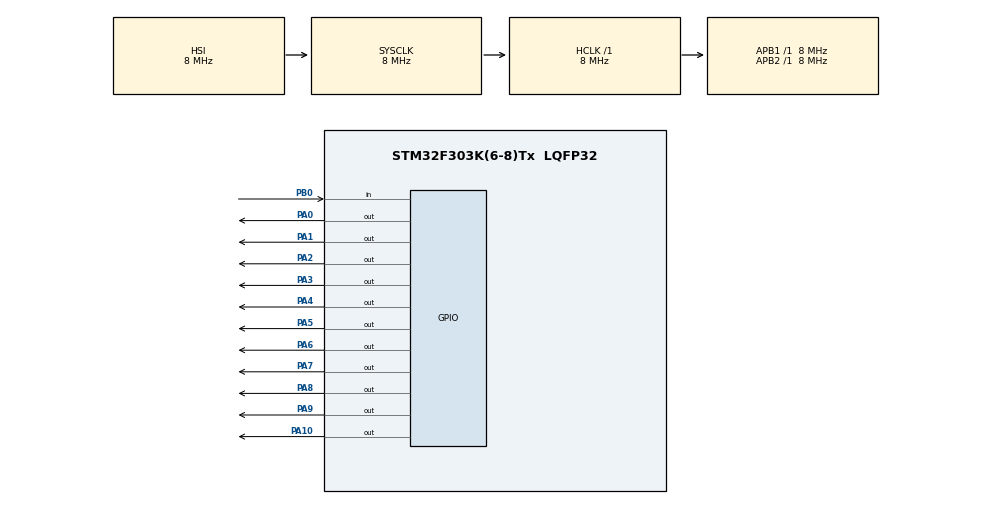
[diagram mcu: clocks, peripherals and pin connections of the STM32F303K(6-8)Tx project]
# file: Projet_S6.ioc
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Mcu.Family=STM32F3
Mcu.Name=STM32F303K(6-8)Tx
Mcu.Package=LQFP32
NVIC.PriorityGroup=NVIC_PRIORITYGROUP_4
NVIC.TIM2_IRQn=true\:0\:0\:false\:false\:true\:true\:true\:true
PA0.Signal=GPIO_Output
PA1.Signal=GPIO_Output
PA10.Signal=GPIO_Output
PA13.GPIO_Label=SWDIO
PA13.Mode=Serial_Wire
PA13.Signal=SYS_JTMS-SWDIO
PA14.GPIO_Label=SWCLK
PA14.Mode=Serial_Wire
PA14.Signal=SYS_JTCK-SWCLK
PA15.GPIO_Label=VCP_RX
PA15.Signal=USART2_RX
PA2.Signal=GPIO_Output
PA3.Signal=GPIO_Output
PA4.Signal=GPIO_Output
PA5.Signal=GPIO_Output
PA6.Signal=GPIO_Output
PA7.Signal=GPIO_Output
PA8.Signal=GPIO_Output
PA9.Signal=GPIO_Output
PB0.Signal=GPIO_Input
PF0\ /\ OSC_IN.GPIO_Label=MCO
PF0\ /\ OSC_IN.Mode=HSE-External-Clock-Source
PF0\ /\ OSC_IN.Signal=RCC_OSC_IN
ProjectManager.HeapSize=0x200
ProjectManager.StackSize=0x400
ProjectManager.TargetToolchain=STM32CubeIDE
RCC.AHBFreq_Value=8000000
RCC.APB1Freq_Value=8000000
RCC.APB2Freq_Value=8000000
RCC.CortexFreq_Value=8000000
RCC.HSE_VALUE=8000000
RCC.HSI_VALUE=8000000
RCC.SYSCLKFreq_VALUE=8000000
TIM2.AutoReloadPreload=TIM_AUTORELOAD_PRELOAD_ENABLE
TIM2.Period=49
TIM2.Prescaler=7199
VP_TIM2_VS_ClockSourceINT.Mode=Internal
board=NUCLEO-F303K8

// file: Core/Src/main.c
/* USER CODE BEGIN Header */
/**
  ******************************************************************************
  * @file           : main.c
  * @brief          : Main program body
  ******************************************************************************
  * @attention
  *
  * Copyright (c) 2025 STMicroelectronics.
  * All rights reserved.
  *
  * This software is licensed under terms that can be found in the LICENSE file
  * in the root directory of this software component.
  * If no LICENSE file comes with this software, it is provided AS-IS.
  *
  ******************************************************************************
  */
/* USER CODE END Header */
#include "main.h"

/* USER CODE BEGIN Includes */
#include "leds.h"
#include "stm32f3xx_it.h"
/* USER CODE END Includes */

TIM_HandleTypeDef htim2;

void SystemClock_Config(void);
static void MX_GPIO_Init(void);
static void MX_TIM2_Init(void);

int main(void)
{

  /* MCU Configuration--------------------------------------------------------*/

  /* Reset of all peripherals, Initializes the Flash interface and the Systick. */
  HAL_Init();

  /* Configure the system clock */
  SystemClock_Config();

  /* Initialize all configured peripherals */
  MX_GPIO_Init();
  MX_TIM2_Init();
  /* USER CODE BEGIN 2 */
  set_leds(0);
  /* USER CODE END 2 */

  /* Infinite loop */
  while (1)
  {

  }
}

void SystemClock_Config(void)
{
  RCC_OscInitTypeDef RCC_OscInitStruct = {0};
  RCC_ClkInitTypeDef RCC_ClkInitStruct = {0};

  /** Initializes the RCC Oscillators according to the specified parameters
  * in the RCC_OscInitTypeDef structure.
  */
  RCC_OscInitStruct.OscillatorType = RCC_OSCILLATORTYPE_HSI;
  RCC_OscInitStruct.HSIState = RCC_HSI_ON;
  RCC_OscInitStruct.HSICalibrationValue = RCC_HSICALIBRATION_DEFAULT;
  RCC_OscInitStruct.PLL.PLLState = RCC_PLL_NONE;
  if (HAL_RCC_OscConfig(&RCC_OscInitStruct) != HAL_OK)
  {
    Error_Handler();
  }

  /** Initializes the CPU, AHB and APB buses clocks
  */
  RCC_ClkInitStruct.ClockType = RCC_CLOCKTYPE_HCLK|RCC_CLOCKTYPE_SYSCLK
                              |RCC_CLOCKTYPE_PCLK1|RCC_CLOCKTYPE_PCLK2;
  RCC_ClkInitStruct.SYSCLKSource = RCC_SYSCLKSOURCE_HSI;
  RCC_ClkInitStruct.AHBCLKDivider = RCC_SYSCLK_DIV1;
  RCC_ClkInitStruct.APB1CLKDivider = RCC_HCLK_DIV1;
  RCC_ClkInitStruct.APB2CLKDivider = RCC_HCLK_DIV1;

  if (HAL_RCC_ClockConfig(&RCC_ClkInitStruct, FLASH_LATENCY_0) != HAL_OK)
  {
    Error_Handler();
  }
}

static void MX_TIM2_Init(void)
{

  TIM_ClockConfigTypeDef sClockSourceConfig = {0};
  TIM_MasterConfigTypeDef sMasterConfig = {0};

  htim2.Instance = TIM2;
  htim2.Init.Prescaler = 7199;
  htim2.Init.CounterMode = TIM_COUNTERMODE_UP;
  htim2.Init.Period = 49;
  htim2.Init.ClockDivision = TIM_CLOCKDIVISION_DIV1;
  htim2.Init.AutoReloadPreload = TIM_AUTORELOAD_PRELOAD_ENABLE;
  if (HAL_TIM_Base_Init(&htim2) != HAL_OK)
  {
    Error_Handler();
  }
  sClockSourceConfig.ClockSource = TIM_CLOCKSOURCE_INTERNAL;
  if (HAL_TIM_ConfigClockSource(&htim2, &sClockSourceConfig) != HAL_OK)
  {
    Error_Handler();
  }
  sMasterConfig.MasterOutputTrigger = TIM_TRGO_RESET;
  sMasterConfig.MasterSlaveMode = TIM_MASTERSLAVEMODE_DISABLE;
  if (HAL_TIMEx_MasterConfigSynchronization(&htim2, &sMasterConfig) != HAL_OK)
  {
    Error_Handler();
  }

}

static void MX_GPIO_Init(void)
{
  GPIO_InitTypeDef GPIO_InitStruct = {0};

  /* GPIO Ports Clock Enable */
  __HAL_RCC_GPIOF_CLK_ENABLE();
  __HAL_RCC_GPIOA_CLK_ENABLE();
  __HAL_RCC_GPIOB_CLK_ENABLE();

  /*Configure GPIO pin Output Level */
  HAL_GPIO_WritePin(GPIOA, GPIO_PIN_0|GPIO_PIN_1|GPIO_PIN_2|GPIO_PIN_3
                          |GPIO_PIN_4|GPIO_PIN_5|GPIO_PIN_6|GPIO_PIN_7
                          |GPIO_PIN_8|GPIO_PIN_9|GPIO_PIN_10, GPIO_PIN_RESET);

  /*Configure GPIO pins : PA0 PA1 PA2 PA3
                           PA4 PA5 PA6 PA7
                           PA8 PA9 PA10 */
  GPIO_InitStruct.Pin = GPIO_PIN_0|GPIO_PIN_1|GPIO_PIN_2|GPIO_PIN_3
                          |GPIO_PIN_4|GPIO_PIN_5|GPIO_PIN_6|GPIO_PIN_7
                          |GPIO_PIN_8|GPIO_PIN_9|GPIO_PIN_10;
  GPIO_InitStruct.Mode = GPIO_MODE_OUTPUT_PP;
  GPIO_InitStruct.Pull = GPIO_NOPULL;
  GPIO_InitStruct.Speed = GPIO_SPEED_FREQ_LOW;
  HAL_GPIO_Init(GPIOA, &GPIO_InitStruct);

  /*Configure GPIO pin : PB0 */
  GPIO_InitStruct.Pin = GPIO_PIN_0;
  GPIO_InitStruct.Mode = GPIO_MODE_INPUT;
  GPIO_InitStruct.Pull = GPIO_NOPULL;
  HAL_GPIO_Init(GPIOB, &GPIO_InitStruct);

  /*Configure GPIO pin : VCP_RX_Pin */
  GPIO_InitStruct.Pin = VCP_RX_Pin;
  GPIO_InitStruct.Mode = GPIO_MODE_AF_PP;
  GPIO_InitStruct.Pull = GPIO_NOPULL;
  GPIO_InitStruct.Speed = GPIO_SPEED_FREQ_HIGH;
  GPIO_InitStruct.Alternate = GPIO_AF7_USART2;
  HAL_GPIO_Init(VCP_RX_GPIO_Port, &GPIO_InitStruct);

}

void Error_Handler(void)
{
  __disable_irq();
  while (1)
  {
  }
}
